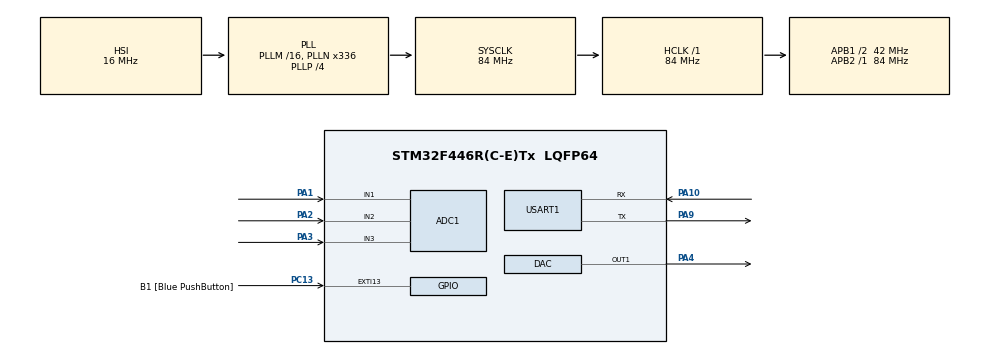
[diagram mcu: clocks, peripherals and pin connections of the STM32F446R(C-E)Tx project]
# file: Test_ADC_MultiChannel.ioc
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ADC1.Channel-0\#ChannelRegularConversion=ADC_CHANNEL_1
ADC1.Channel-1\#ChannelRegularConversion=ADC_CHANNEL_1
ADC1.Channel-2\#ChannelRegularConversion=ADC_CHANNEL_1
ADC1.ContinuousConvMode=DISABLE
ADC1.ExternalTrigConv=ADC_EXTERNALTRIGCONV_T3_TRGO
ADC1.NbrOfConversion=3
ADC1.NbrOfConversionFlag=1
ADC1.Rank-0\#ChannelRegularConversion=1
ADC1.Rank-1\#ChannelRegularConversion=2
ADC1.Rank-2\#ChannelRegularConversion=3
ADC1.SamplingTime-0\#ChannelRegularConversion=ADC_SAMPLETIME_3CYCLES
ADC1.SamplingTime-1\#ChannelRegularConversion=ADC_SAMPLETIME_3CYCLES
ADC1.SamplingTime-2\#ChannelRegularConversion=ADC_SAMPLETIME_3CYCLES
ADC1.ScanConvMode=ENABLE
ADC1.master=1
DAC.DAC_Trigger=DAC_TRIGGER_T2_TRGO
Dma.ADC1.1.Direction=DMA_PERIPH_TO_MEMORY
Dma.ADC1.1.FIFOMode=DMA_FIFOMODE_DISABLE
Dma.ADC1.1.Instance=DMA2_Stream0
Dma.ADC1.1.MemDataAlignment=DMA_MDATAALIGN_WORD
Dma.ADC1.1.MemInc=DMA_MINC_ENABLE
Dma.ADC1.1.Mode=DMA_NORMAL
Dma.ADC1.1.PeriphDataAlignment=DMA_PDATAALIGN_WORD
Dma.ADC1.1.PeriphInc=DMA_PINC_DISABLE
Dma.ADC1.1.Priority=DMA_PRIORITY_LOW
Dma.DAC1.0.Direction=DMA_MEMORY_TO_PERIPH
Dma.DAC1.0.FIFOMode=DMA_FIFOMODE_DISABLE
Dma.DAC1.0.Instance=DMA1_Stream5
Dma.DAC1.0.MemDataAlignment=DMA_MDATAALIGN_HALFWORD
Dma.DAC1.0.MemInc=DMA_MINC_ENABLE
Dma.DAC1.0.Mode=DMA_CIRCULAR
Dma.DAC1.0.PeriphDataAlignment=DMA_PDATAALIGN_HALFWORD
Dma.DAC1.0.PeriphInc=DMA_PINC_DISABLE
Dma.DAC1.0.Priority=DMA_PRIORITY_HIGH
Dma.Request0=DAC1
Dma.Request1=ADC1
Mcu.Family=STM32F4
Mcu.Name=STM32F446R(C-E)Tx
Mcu.Package=LQFP64
NVIC.DMA1_Stream5_IRQn=true\:0\:0\:false\:false\:true\:false\:true
NVIC.DMA2_Stream0_IRQn=true\:0\:0\:false\:false\:true\:false\:true
NVIC.PriorityGroup=NVIC_PRIORITYGROUP_0
PA1.Signal=ADCx_IN1
PA10.Mode=Asynchronous
PA10.Signal=USART1_RX
PA13.GPIO_Label=TMS
PA13.Mode=Serial_Wire
PA13.Signal=SYS_JTMS-SWDIO
PA14.GPIO_Label=TCK
PA14.Mode=Serial_Wire
PA14.Signal=SYS_JTCK-SWCLK
PA2.Signal=ADCx_IN2
PA3.Signal=ADCx_IN3
PA4.Signal=COMP_DAC1_group
PA9.Mode=Asynchronous
PA9.Signal=USART1_TX
PB3.GPIO_Label=SWO
PB3.Signal=SYS_JTDO-SWO
PC13.GPIO_Label=B1 [Blue PushButton]
PC13.GPIO_ModeDefaultEXTI=GPIO_MODE_IT_FALLING
PC13.Signal=GPXTI13
PC14-OSC32_IN.Mode=LSE-External-Oscillator
PC14-OSC32_IN.Signal=RCC_OSC32_IN
PC15-OSC32_OUT.Mode=LSE-External-Oscillator
PC15-OSC32_OUT.Signal=RCC_OSC32_OUT
PH0-OSC_IN.Mode=HSE-External-Oscillator
PH0-OSC_IN.Signal=RCC_OSC_IN
PH1-OSC_OUT.Mode=HSE-External-Oscillator
PH1-OSC_OUT.Signal=RCC_OSC_OUT
ProjectManager.HeapSize=0x200
ProjectManager.StackSize=0x400
ProjectManager.TargetToolchain=MDK-ARM V5
RCC.48MHZClocksFreq_Value=84000000
RCC.AHBFreq_Value=84000000
RCC.APB1CLKDivider=RCC_HCLK_DIV2
RCC.APB1Freq_Value=42000000
RCC.APB1TimFreq_Value=84000000
RCC.APB2Freq_Value=84000000
RCC.APB2TimFreq_Value=84000000
RCC.CortexFreq_Value=84000000
RCC.FLatency-AdvancedSettings=FLASH_LATENCY_2
RCC.HCLKFreq_Value=84000000
RCC.HSE_VALUE=8000000
RCC.HSI_VALUE=16000000
RCC.PLLN=336
RCC.PLLP=RCC_PLLP_DIV4
RCC.SYSCLKFreq_VALUE=84000000
RCC.SYSCLKSource=RCC_SYSCLKSOURCE_PLLCLK
RCC.USBFreq_Value=168000000
RCC.VCOOutputFreq_Value=336000000
SH.ADCx_IN1.0=ADC1_IN1,IN1
SH.ADCx_IN2.0=ADC1_IN2,IN2
SH.ADCx_IN3.0=ADC1_IN3,IN3
SH.COMP_DAC1_group.0=DAC_OUT1,DAC_OUT1
TIM2.AutoReloadPreload=TIM_AUTORELOAD_PRELOAD_ENABLE
TIM2.Period=250
TIM2.Prescaler=4
TIM2.TIM_MasterOutputTrigger=TIM_TRGO_UPDATE
TIM3.AutoReloadPreload=TIM_AUTORELOAD_PRELOAD_ENABLE
TIM3.Period=199
TIM3.Prescaler=199
TIM3.TIM_MasterOutputTrigger=TIM_TRGO_UPDATE
USART1.VirtualMode=VM_ASYNC
VP_TIM2_VS_ClockSourceINT.Mode=Internal
VP_TIM3_VS_ClockSourceINT.Mode=Internal
board=NUCLEO-F446RE

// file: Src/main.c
/* USER CODE BEGIN Header */
/**
  ******************************************************************************
  * @file           : main.c
  * @brief          : Main program body
  ******************************************************************************
  * @attention
  *
  * <h2><center>&copy; Copyright (c) 2019 STMicroelectronics.
  * All rights reserved.</center></h2>
  *
  * This software component is licensed by ST under BSD 3-Clause license,
  * the "License"; You may not use this file except in compliance with the
  * License. You may obtain a copy of the License at:
  *                        opensource.org/licenses/BSD-3-Clause
  *
  ******************************************************************************
  */
/* USER CODE END Header */

#include "main.h"

/* USER CODE BEGIN PD */
#define PI2 6.28318530717959
#define Sine_Length 64
/* USER CODE END PD */

ADC_HandleTypeDef hadc1;
DMA_HandleTypeDef hdma_adc1;

DAC_HandleTypeDef hdac;
DMA_HandleTypeDef hdma_dac1;

TIM_HandleTypeDef htim2;
TIM_HandleTypeDef htim3;

UART_HandleTypeDef huart1;

/* USER CODE BEGIN PV */
uint32_t ADC_Value[100];
uint32_t sinewave_val[Sine_Length];
/* USER CODE END PV */

void SystemClock_Config(void);
static void MX_GPIO_Init(void);
static void MX_DMA_Init(void);
static void MX_ADC1_Init(void);
static void MX_USART1_UART_Init(void);
static void MX_TIM3_Init(void);
static void MX_DAC_Init(void);
static void MX_TIM2_Init(void);
void Sine_CalValue(uint32_t* pdata, uint16_t datasize);

int main(void)
{

  /* MCU Configuration--------------------------------------------------------*/

  /* Reset of all peripherals, Initializes the Flash interface and the Systick. */
  HAL_Init();

  /* Configure the system clock */
  SystemClock_Config();

  /* Initialize all configured peripherals */
	Sine_CalValue(sinewave_val,64);
  MX_GPIO_Init();
  MX_DMA_Init();
  MX_ADC1_Init();
  MX_USART1_UART_Init();
  MX_TIM3_Init();
  MX_DAC_Init();
  MX_TIM2_Init();
  /* USER CODE BEGIN 2 */
	HAL_TIM_Base_Start(&htim2);//打开定时器
	HAL_TIM_Base_Start(&htim3);//打开定时器
	HAL_ADC_Start_DMA(&hadc1, (uint32_t*)&ADC_Value, 100);//开启ADC的DMA,ADC_Value缓存数据
	HAL_DAC_Start_DMA(&hdac,DAC_CHANNEL_1,(uint32_t *)sinewave_val,Sine_Length,DAC_ALIGN_12B_R);
  /* USER CODE END 2 */

  /* Infinite loop */
  while (1)
  {
		HAL_Delay(10);
  }
}
/**
  * @brief Calculate Values of a Sinewave
	& @param * @pdata pointer of the data @datasize size of the pointer
  * @retval None
  */
void Sine_CalValue(uint32_t* pdata, uint16_t datasize)
{
	for(int i=0; i<datasize; i++)
	{
		pdata[i] = 37.5*sin(PI2*i/64.0) + 1500;
	}
}
void SystemClock_Config(void)
{
  RCC_OscInitTypeDef RCC_OscInitStruct = {0};
  RCC_ClkInitTypeDef RCC_ClkInitStruct = {0};

  /** Configure the main internal regulator output voltage
  */
  __HAL_RCC_PWR_CLK_ENABLE();
  __HAL_PWR_VOLTAGESCALING_CONFIG(PWR_REGULATOR_VOLTAGE_SCALE3);
  /** Initializes the CPU, AHB and APB busses clocks
  */
  RCC_OscInitStruct.OscillatorType = RCC_OSCILLATORTYPE_HSI;
  RCC_OscInitStruct.HSIState = RCC_HSI_ON;
  RCC_OscInitStruct.HSICalibrationValue = RCC_HSICALIBRATION_DEFAULT;
  RCC_OscInitStruct.PLL.PLLState = RCC_PLL_ON;
  RCC_OscInitStruct.PLL.PLLSource = RCC_PLLSOURCE_HSI;
  RCC_OscInitStruct.PLL.PLLM = 16;
  RCC_OscInitStruct.PLL.PLLN = 336;
  RCC_OscInitStruct.PLL.PLLP = RCC_PLLP_DIV4;
  RCC_OscInitStruct.PLL.PLLQ = 2;
  RCC_OscInitStruct.PLL.PLLR = 2;
  if (HAL_RCC_OscConfig(&RCC_OscInitStruct) != HAL_OK)
  {
    Error_Handler();
  }
  /** Initializes the CPU, AHB and APB busses clocks
  */
  RCC_ClkInitStruct.ClockType = RCC_CLOCKTYPE_HCLK|RCC_CLOCKTYPE_SYSCLK
                              |RCC_CLOCKTYPE_PCLK1|RCC_CLOCKTYPE_PCLK2;
  RCC_ClkInitStruct.SYSCLKSource = RCC_SYSCLKSOURCE_PLLCLK;
  RCC_ClkInitStruct.AHBCLKDivider = RCC_SYSCLK_DIV1;
  RCC_ClkInitStruct.APB1CLKDivider = RCC_HCLK_DIV2;
  RCC_ClkInitStruct.APB2CLKDivider = RCC_HCLK_DIV1;

  if (HAL_RCC_ClockConfig(&RCC_ClkInitStruct, FLASH_LATENCY_2) != HAL_OK)
  {
    Error_Handler();
  }
}

static void MX_ADC1_Init(void)
{

  ADC_ChannelConfTypeDef sConfig = {0};

  /** Configure the global features of the ADC (Clock, Resolution, Data Alignment and number of conversion)
  */
  hadc1.Instance = ADC1;
  hadc1.Init.ClockPrescaler = ADC_CLOCK_SYNC_PCLK_DIV4;
  hadc1.Init.Resolution = ADC_RESOLUTION_12B;
  hadc1.Init.ScanConvMode = ENABLE;
  hadc1.Init.ContinuousConvMode = DISABLE;
  hadc1.Init.DiscontinuousConvMode = DISABLE;
  hadc1.Init.ExternalTrigConvEdge = ADC_EXTERNALTRIGCONVEDGE_RISING;
  hadc1.Init.ExternalTrigConv = ADC_EXTERNALTRIGCONV_T3_TRGO;
  hadc1.Init.DataAlign = ADC_DATAALIGN_RIGHT;
  hadc1.Init.NbrOfConversion = 3;
  hadc1.Init.DMAContinuousRequests = DISABLE;
  hadc1.Init.EOCSelection = ADC_EOC_SINGLE_CONV;
  if (HAL_ADC_Init(&hadc1) != HAL_OK)
  {
    Error_Handler();
  }
  /** Configure for the selected ADC regular channel its corresponding rank in the sequencer and its sample time.
  */
  sConfig.Channel = ADC_CHANNEL_1;
  sConfig.Rank = 1;
  sConfig.SamplingTime = ADC_SAMPLETIME_3CYCLES;
  if (HAL_ADC_ConfigChannel(&hadc1, &sConfig) != HAL_OK)
  {
    Error_Handler();
  }
  /** Configure for the selected ADC regular channel its corresponding rank in the sequencer and its sample time.
  */
  sConfig.Rank = 2;
  if (HAL_ADC_ConfigChannel(&hadc1, &sConfig) != HAL_OK)
  {
    Error_Handler();
  }
  /** Configure for the selected ADC regular channel its corresponding rank in the sequencer and its sample time.
  */
  sConfig.Rank = 3;
  if (HAL_ADC_ConfigChannel(&hadc1, &sConfig) != HAL_OK)
  {
    Error_Handler();
  }

}

static void MX_DAC_Init(void)
{

  DAC_ChannelConfTypeDef sConfig = {0};

  /** DAC Initialization
  */
  hdac.Instance = DAC;
  if (HAL_DAC_Init(&hdac) != HAL_OK)
  {
    Error_Handler();
  }
  /** DAC channel OUT1 config
  */
  sConfig.DAC_Trigger = DAC_TRIGGER_T2_TRGO;
  sConfig.DAC_OutputBuffer = DAC_OUTPUTBUFFER_ENABLE;
  if (HAL_DAC_ConfigChannel(&hdac, &sConfig, DAC_CHANNEL_1) != HAL_OK)
  {
    Error_Handler();
  }

}

static void MX_TIM2_Init(void)
{

  TIM_ClockConfigTypeDef sClockSourceConfig = {0};
  TIM_MasterConfigTypeDef sMasterConfig = {0};

  htim2.Instance = TIM2;
  htim2.Init.Prescaler = 4;
  htim2.Init.CounterMode = TIM_COUNTERMODE_UP;
  htim2.Init.Period = 250;
  htim2.Init.ClockDivision = TIM_CLOCKDIVISION_DIV1;
  htim2.Init.AutoReloadPreload = TIM_AUTORELOAD_PRELOAD_ENABLE;
  if (HAL_TIM_Base_Init(&htim2) != HAL_OK)
  {
    Error_Handler();
  }
  sClockSourceConfig.ClockSource = TIM_CLOCKSOURCE_INTERNAL;
  if (HAL_TIM_ConfigClockSource(&htim2, &sClockSourceConfig) != HAL_OK)
  {
    Error_Handler();
  }
  sMasterConfig.MasterOutputTrigger = TIM_TRGO_UPDATE;
  sMasterConfig.MasterSlaveMode = TIM_MASTERSLAVEMODE_DISABLE;
  if (HAL_TIMEx_MasterConfigSynchronization(&htim2, &sMasterConfig) != HAL_OK)
  {
    Error_Handler();
  }

}

static void MX_TIM3_Init(void)
{

  TIM_ClockConfigTypeDef sClockSourceConfig = {0};
  TIM_MasterConfigTypeDef sMasterConfig = {0};

  htim3.Instance = TIM3;
  htim3.Init.Prescaler = 199;
  htim3.Init.CounterMode = TIM_COUNTERMODE_UP;
  htim3.Init.Period = 199;
  htim3.Init.ClockDivision = TIM_CLOCKDIVISION_DIV1;
  htim3.Init.AutoReloadPreload = TIM_AUTORELOAD_PRELOAD_ENABLE;
  if (HAL_TIM_Base_Init(&htim3) != HAL_OK)
  {
    Error_Handler();
  }
  sClockSourceConfig.ClockSource = TIM_CLOCKSOURCE_INTERNAL;
  if (HAL_TIM_ConfigClockSource(&htim3, &sClockSourceConfig) != HAL_OK)
  {
    Error_Handler();
  }
  sMasterConfig.MasterOutputTrigger = TIM_TRGO_UPDATE;
  sMasterConfig.MasterSlaveMode = TIM_MASTERSLAVEMODE_DISABLE;
  if (HAL_TIMEx_MasterConfigSynchronization(&htim3, &sMasterConfig) != HAL_OK)
  {
    Error_Handler();
  }

}

static void MX_USART1_UART_Init(void)
{

  huart1.Instance = USART1;
  huart1.Init.BaudRate = 115200;
  huart1.Init.WordLength = UART_WORDLENGTH_8B;
  huart1.Init.StopBits = UART_STOPBITS_1;
  huart1.Init.Parity = UART_PARITY_NONE;
  huart1.Init.Mode = UART_MODE_TX_RX;
  huart1.Init.HwFlowCtl = UART_HWCONTROL_NONE;
  huart1.Init.OverSampling = UART_OVERSAMPLING_16;
  if (HAL_UART_Init(&huart1) != HAL_OK)
  {
    Error_Handler();
  }

}

static void MX_DMA_Init(void)
{

  /* DMA controller clock enable */
  __HAL_RCC_DMA1_CLK_ENABLE();
  __HAL_RCC_DMA2_CLK_ENABLE();

  /* DMA interrupt init */
  /* DMA1_Stream5_IRQn interrupt configuration */
  HAL_NVIC_SetPriority(DMA1_Stream5_IRQn, 0, 0);
  HAL_NVIC_EnableIRQ(DMA1_Stream5_IRQn);
  /* DMA2_Stream0_IRQn interrupt configuration */
  HAL_NVIC_SetPriority(DMA2_Stream0_IRQn, 0, 0);
  HAL_NVIC_EnableIRQ(DMA2_Stream0_IRQn);

}

static void MX_GPIO_Init(void)
{
  GPIO_InitTypeDef GPIO_InitStruct = {0};

  /* GPIO Ports Clock Enable */
  __HAL_RCC_GPIOC_CLK_ENABLE();
  __HAL_RCC_GPIOH_CLK_ENABLE();
  __HAL_RCC_GPIOA_CLK_ENABLE();
  __HAL_RCC_GPIOB_CLK_ENABLE();

  /*Configure GPIO pin : B1_Pin */
  GPIO_InitStruct.Pin = B1_Pin;
  GPIO_InitStruct.Mode = GPIO_MODE_IT_FALLING;
  GPIO_InitStruct.Pull = GPIO_NOPULL;
  HAL_GPIO_Init(B1_GPIO_Port, &GPIO_InitStruct);

}

void Error_Handler(void)
{
}

/************************ (C) COPYRIGHT STMicroelectronics *****END OF FILE****/
